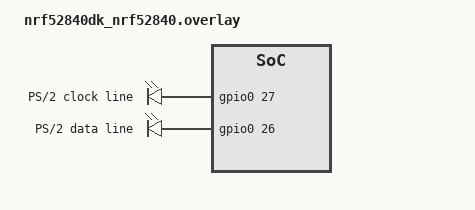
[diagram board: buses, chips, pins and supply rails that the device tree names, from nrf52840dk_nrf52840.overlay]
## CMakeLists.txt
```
# SPDX-License-Identifier: Apache-2.0

cmake_minimum_required(VERSION 3.13.1)
find_package(Zephyr REQUIRED HINTS $ENV{ZEPHYR_BASE})
project(peripheral_hids)

target_include_directories(app PRIVATE src/inc)

FILE(GLOB app_sources src/*.c)
target_sources(app PRIVATE
  ${app_sources}
  )
```

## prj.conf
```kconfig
# Incresed stack due to settings API usage
CONFIG_SYSTEM_WORKQUEUE_STACK_SIZE=2048

CONFIG_BT=y
CONFIG_BT_DEBUG_LOG=y
CONFIG_BT_SMP=y
CONFIG_BT_PERIPHERAL=y
CONFIG_BT_DIS=y
CONFIG_BT_BAS=y
CONFIG_BT_DEVICE_NAME="PS2 to bluetooth keyboard adapter"
CONFIG_BT_DEVICE_APPEARANCE=962

CONFIG_BT_SETTINGS=y
CONFIG_FLASH=y
CONFIG_FLASH_PAGE_LAYOUT=y
CONFIG_FLASH_MAP=y
CONFIG_NVS=y
CONFIG_SETTINGS=y
```

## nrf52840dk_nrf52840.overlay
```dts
/ {
    ps2 {
        compatible = "gpio-leds";
        status = "okay";        
        ps2_clk: ps2clk {
            gpios = < &gpio0 27 GPIO_ACTIVE_HIGH >;
            label = "PS/2 clock line";
        };
        ps2_data: ps2data{
            gpios = < &gpio0 26 GPIO_ACTIVE_HIGH >;
            label = "PS/2 data line";
        };
    };
    aliases {
        ps2clk = &ps2_clk;
        ps2data = &ps2_data;
    };    
};

&i2c0{
    status = "disabled";        
};
&i2c1{
    status = "disabled";        
};
```

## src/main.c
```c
/* main.c - Application main entry point */

/*
 * Copyright (c) 2016 Intel Corporation
 *
 * SPDX-License-Identifier: Apache-2.0
 */

#include <zephyr/types.h>
#include <stddef.h>
#include <string.h>
#include <errno.h>
#include <sys/printk.h>
#include <sys/byteorder.h>
#include <zephyr.h>

#include <settings/settings.h>

#include <bluetooth/bluetooth.h>
#include <bluetooth/hci.h>
#include <bluetooth/conn.h>
#include <bluetooth/uuid.h>
#include <bluetooth/gatt.h>

#include "hog.h"
#include "ps2_keyboard.h"
#include "bt_hid_tools.h"

static const struct bt_data ad[] = {
	BT_DATA_BYTES(BT_DATA_FLAGS, (BT_LE_AD_GENERAL | BT_LE_AD_NO_BREDR)),
	BT_DATA_BYTES(BT_DATA_UUID16_ALL,
		      BT_UUID_16_ENCODE(BT_UUID_HIDS_VAL),
		      BT_UUID_16_ENCODE(BT_UUID_BAS_VAL)),
};

static void connected(struct bt_conn *conn, uint8_t err)
{
	char addr[BT_ADDR_LE_STR_LEN];

	bt_addr_le_to_str(bt_conn_get_dst(conn), addr, sizeof(addr));

	if (err) {
		printk("Failed to connect to %s (%u)\n", addr, err);
		return;
	}

	printk("Connected %s\n", addr);

	if (bt_conn_set_security(conn, BT_SECURITY_L2)) {
		printk("Failed to set security\n");
	}
}

static void disconnected(struct bt_conn *conn, uint8_t reason)
{
	char addr[BT_ADDR_LE_STR_LEN];

	bt_addr_le_to_str(bt_conn_get_dst(conn), addr, sizeof(addr));

	printk("Disconnected from %s (reason 0x%02x)\n", addr, reason);
}

static void security_changed(struct bt_conn *conn, bt_security_t level,
			     enum bt_security_err err)
{
	char addr[BT_ADDR_LE_STR_LEN];

	bt_addr_le_to_str(bt_conn_get_dst(conn), addr, sizeof(addr));

	if (!err) {
		printk("Security changed: %s level %u\n", addr, level);
	} else {
		printk("Security failed: %s level %u err %d\n", addr, level,
		       err);
	}
}

static struct bt_conn_cb conn_callbacks = {
	.connected = connected,
	.disconnected = disconnected,
	.security_changed = security_changed,
};

static void bt_ready(int err)
{
	if (err) {
		printk("Bluetooth init failed (err %d)\n", err);
		return;
	}

	printk("Bluetooth initialized\n");

	hog_init();

	if (IS_ENABLED(CONFIG_SETTINGS)) {
		settings_load();
	}

	err = bt_le_adv_start(BT_LE_ADV_CONN_NAME, ad, ARRAY_SIZE(ad), NULL, 0);
	if (err) {
		printk("Advertising failed to start (err %d)\n", err);
		return;
	}

	printk("Advertising successfully started\n");
}

static void auth_passkey_display(struct bt_conn *conn, unsigned int passkey)
{
	char addr[BT_ADDR_LE_STR_LEN];

	bt_addr_le_to_str(bt_conn_get_dst(conn), addr, sizeof(addr));

	printk("Passkey for %s: %06u\n", addr, passkey);
}

static void auth_cancel(struct bt_conn *conn)
{
	char addr[BT_ADDR_LE_STR_LEN];

	bt_addr_le_to_str(bt_conn_get_dst(conn), addr, sizeof(addr));

	printk("Pairing cancelled: %s\n", addr);
}

static struct bt_conn_auth_cb auth_cb_display = {
	.passkey_display = auth_passkey_display,
	.passkey_entry = NULL,
	.cancel = auth_cancel,
};

void main(void)
{
	int err;

	ps2_keyboard_init();

	err = bt_enable(bt_ready);
	if (err) {
		printk("Bluetooth init failed (err %d)\n", err);
		return;
	}

	bt_conn_cb_register(&conn_callbacks);
	bt_conn_auth_cb_register(&auth_cb_display);
	
	int i=0;
	while(1){
		i++;
	    // ps2_keyboard_set_leds(i&1, i&2, i&3 );
		if ( i % 10 == 0) keyboard_print("I'm writing on your keyboard!");
		printk("ps2_keyboard_set_leds\n");
		k_msleep(1000);
		// i%=4;
	}
}
```

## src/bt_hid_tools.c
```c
#include "bt_hid_tools.h"

#include <stdint.h>
#include <zephyr.h>

#include "hog.h"
#include "usb_hid_keys.h"


void keyboard_print(const char* str){
	struct hids_report_keyboard key_report = { .modifier = 0};

	while(*str){
		key_report.keycode[5] = 0;
		hog_set_keyboard_input(&key_report);
		k_msleep(100);
		key_report.keycode[5] = ascii_to_hid(*str++);
		hog_set_keyboard_input(&key_report);
		k_msleep(100);
	}
	
	key_report.keycode[5] = 0;
	hog_set_keyboard_input(&key_report);	
}

int ascii_to_hid(uint8_t ascii)
{
	if (ascii < 32) {
		/* Character not supported */
		return -1;
	} else if (ascii < 48) {
		/* Special characters */
		switch (ascii) {
		case 32:
			return KEY_SPACE;
		case 33:
			return KEY_1;
		case 34:
			return KEY_APOSTROPHE;
		case 35:
			return KEY_3;
		case 36:
			return KEY_4;
		case 37:
			return KEY_5;
		case 38:
			return KEY_7;
		case 39:
			return KEY_APOSTROPHE;
		case 40:
			return KEY_9;
		case 41:
			return KEY_0;
		case 42:
			return KEY_8;
		case 43:
			return KEY_EQUAL;
		case 44:
			return KEY_COMMA;
		case 45:
			return KEY_MINUS;
		case 46:
			return KEY_DOT;
		case 47:
			return KEY_SLASH;
		default:
			return -1;
		}
	} else if (ascii < 58) {
		/* Numbers */
		if (ascii == 48U) {
			return KEY_0;
		} else {
			return ascii - 19;
		}
	} else if (ascii < 65) {
		/* Special characters #2 */
		switch (ascii) {
		case 58:
			return KEY_SEMICOLON;
		case 59:
			return KEY_SEMICOLON;
		case 60:
			return KEY_COMMA;
		case 61:
			return KEY_EQUAL;
		case 62:
			return KEY_DOT;
		case 63:
			return KEY_SLASH;
		case 64:
			return KEY_2;
		default:
			return -1;
		}
	} else if (ascii < 91) {
		/* Uppercase characters */
		return ascii - 61U;
	} else if (ascii < 97) {
		/* Special characters #3 */
		switch (ascii) {
		case 91:
			return KEY_LEFTBRACE;
		case 92:
			return KEY_BACKSLASH;
		case 93:
			return KEY_RIGHTBRACE;
		case 94:
			return KEY_6;
		case 95:
			return KEY_MINUS;
		case 96:
			return KEY_GRAVE;
		default:
			return -1;
		}
	} else if (ascii < 123) {
		/* Lowercase letters */
		return ascii - 93;
	} else if (ascii < 128) {
		/* Special characters #4 */
		switch (ascii) {
		case 123:
			return KEY_LEFTBRACE;
		case 124:
			return KEY_BACKSLASH;
		case 125:
			return KEY_RIGHTBRACE;
		case 126:
			return KEY_GRAVE;
		case 127:
			return KEY_DELETE;
		default:
			return -1;
		}
	}

	return -1;
}
```

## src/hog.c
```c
/** @file
 *  @brief HoG Service sample
 */

/*
 * Copyright (c) 2016 Intel Corporation
 *
 * SPDX-License-Identifier: Apache-2.0
 */

#include <zephyr/types.h>
#include <stddef.h>
#include <string.h>
#include <errno.h>
#include <sys/printk.h>
#include <sys/byteorder.h>
#include <zephyr.h>

#include <bluetooth/bluetooth.h>
#include <bluetooth/hci.h>
#include <bluetooth/conn.h>
#include <bluetooth/uuid.h>
#include <bluetooth/gatt.h>

#include "usb_hid_keys.h"

enum {
	HIDS_REMOTE_WAKE = BIT(0),
	HIDS_NORMALLY_CONNECTABLE = BIT(1),
};

struct hids_info {
	uint16_t version; /* version number of base USB HID Specification */
	uint8_t code; /* country HID Device hardware is localized for. */
	uint8_t flags;
} __packed;

struct hids_report_mouse {
	uint8_t id; /* report id */
	uint8_t type; /* report type */
} __packed;

struct hids_report_keyboard{
	uint8_t modifier;
	uint8_t reserved;
	uint8_t keycode[6];
} __packed;

static struct hids_info info = {
	.version = 0x0000,
	.code = 0x00,
	.flags = HIDS_NORMALLY_CONNECTABLE,
};

enum {
	HIDS_INPUT = 0x01,
	HIDS_OUTPUT = 0x02,
	HIDS_FEATURE = 0x03,
};

static struct hids_report_mouse input_mouse = {
	.id = 0x01,
	.type = HIDS_INPUT,
};

static struct hids_report_keyboard input_keyboard = {
	.modifier = 0x00,
};

static uint8_t simulate_input;
static uint8_t ctrl_point;
static uint8_t report_map_mouse[] = {
	0x05, 0x01, /* Usage Page (Generic Desktop Ctrls) */
	0x09, 0x02, /* Usage (Mouse) */
	0xA1, 0x01, /* Collection (Application) */
	0x09, 0x01, /*   Usage (Pointer) */
	0xA1, 0x00, /*   Collection (Physical) */
	0x05, 0x09, /*     Usage Page (Button) */
	0x19, 0x01, /*     Usage Minimum (0x01) */
	0x29, 0x03, /*     Usage Maximum (0x03) */
	0x15, 0x00, /*     Logical Minimum (0) */
	0x25, 0x01, /*     Logical Maximum (1) */
	0x95, 0x03, /*     Report Count (3) */
	0x75, 0x01, /*     Report Size (1) */
	0x81, 0x02, /*     Input (Data,Var,Abs,No Wrap,Linear,...) */
	0x95, 0x01, /*     Report Count (1) */
	0x75, 0x05, /*     Report Size (5) */
	0x81, 0x03, /*     Input (Const,Var,Abs,No Wrap,Linear,...) */
	0x05, 0x01, /*     Usage Page (Generic Desktop Ctrls) */
	0x09, 0x30, /*     Usage (X) */
	0x09, 0x31, /*     Usage (Y) */
	0x15, 0x81, /*     Logical Minimum (129) */
	0x25, 0x7F, /*     Logical Maximum (127) */
	0x75, 0x08, /*     Report Size (8) */
	0x95, 0x02, /*     Report Count (2) */
	0x81, 0x06, /*     Input (Data,Var,Rel,No Wrap,Linear,...) */
	0xC0,       /*   End Collection */
	0xC0,       /* End Collection */
};

//From http://codeandlife.com/2012/06/18/usb-hid-keyboard-with-v-usb/
static const uint8_t report_map[63] = {   /* USB report descriptor */
    0x05, 0x01,                    // USAGE_PAGE (Generic Desktop)
    0x09, 0x06,                    // USAGE (Keyboard)
    0xa1, 0x01,                    // COLLECTION (Application)
    0x75, 0x01,                    //   REPORT_SIZE (1)
    0x95, 0x08,                    //   REPORT_COUNT (8)
    0x05, 0x07,                    //   USAGE_PAGE (Keyboard)(Key Codes)
    0x19, 0xe0,                    //   USAGE_MINIMUM (Keyboard LeftControl)(224)
    0x29, 0xe7,                    //   USAGE_MAXIMUM (Keyboard Right GUI)(231)
    0x15, 0x00,                    //   LOGICAL_MINIMUM (0)
    0x25, 0x01,                    //   LOGICAL_MAXIMUM (1)
    0x81, 0x02,                    //   INPUT (Data,Var,Abs) ; Modifier byte
    0x95, 0x01,                    //   REPORT_COUNT (1)
    0x75, 0x08,                    //   REPORT_SIZE (8)
    0x81, 0x03,                    //   INPUT (Cnst,Var,Abs) ; Reserved byte
    0x95, 0x05,                    //   REPORT_COUNT (5)
    0x75, 0x01,                    //   REPORT_SIZE (1)
    0x05, 0x08,                    //   USAGE_PAGE (LEDs)
    0x19, 0x01,                    //   USAGE_MINIMUM (Num Lock)
    0x29, 0x05,                    //   USAGE_MAXIMUM (Kana)
    0x91, 0x02,                    //   OUTPUT (Data,Var,Abs) ; LED report
    0x95, 0x01,                    //   REPORT_COUNT (1)
    0x75, 0x03,                    //   REPORT_SIZE (3)
    0x91, 0x03,                    //   OUTPUT (Cnst,Var,Abs) ; LED report padding
    0x95, 0x06,                    //   REPORT_COUNT (6)
    0x75, 0x08,                    //   REPORT_SIZE (8)
    0x15, 0x00,                    //   LOGICAL_MINIMUM (0)
    0x25, 167,                     //   LOGICAL_MAXIMUM (167)  (Normally would be 101, but we want volume buttons)
    0x05, 0x07,                    //   USAGE_PAGE (Keyboard)(Key Codes)
    0x19, 0x00,                    //   USAGE_MINIMUM (Reserved (no event indicated))(0)
    0x29, 167,                     //   USAGE_MAXIMUM (Keyboard Application)(101) (Now 167)
    0x81, 0x00,                    //   INPUT (Data,Ary,Abs)
    0xc0                           // END_COLLECTION
};


static ssize_t read_info(struct bt_conn *conn,
			  const struct bt_gatt_attr *attr, void *buf,
			  uint16_t len, uint16_t offset)
{
	return bt_gatt_attr_read(conn, attr, buf, len, offset, attr->user_data,
				 sizeof(struct hids_info));
}

static ssize_t read_report_map(struct bt_conn *conn,
			       const struct bt_gatt_attr *attr, void *buf,
			       uint16_t len, uint16_t offset)
{
	printk("read_report_map\n");
	return bt_gatt_attr_read(conn, attr, buf, len, offset, report_map,
				 sizeof(report_map));
}

static ssize_t read_report(struct bt_conn *conn,
			   const struct bt_gatt_attr *attr, void *buf,
			   uint16_t len, uint16_t offset)
{
	printk("read_report called, attr = %p\n",attr);
	return bt_gatt_attr_read(conn, attr, buf, len, offset, attr->user_data,
				 sizeof(struct hids_report_keyboard));
}

static void input_ccc_changed(const struct bt_gatt_attr *attr, uint16_t value)
{
	printk("input_ccc_changed\n");
	simulate_input = (value == BT_GATT_CCC_NOTIFY) ? 1 : 0;
}

static ssize_t read_input_report(struct bt_conn *conn,
				 const struct bt_gatt_attr *attr, void *buf,
				 uint16_t len, uint16_t offset)
{
	printk("read_input_report\n");
	return bt_gatt_attr_read(conn, attr, buf, len, offset, NULL, 0);
}

static ssize_t write_ctrl_point(struct bt_conn *conn,
				const struct bt_gatt_attr *attr,
				const void *buf, uint16_t len, uint16_t offset,
				uint8_t flags)
{
	uint8_t *value = attr->user_data;

	if (offset + len > sizeof(ctrl_point)) {
		return BT_GATT_ERR(BT_ATT_ERR_INVALID_OFFSET);
	}

	memcpy(value + offset, buf, len);

	return len;
}

/* HID Service Declaration */
BT_GATT_SERVICE_DEFINE(hog_svc,
	BT_GATT_PRIMARY_SERVICE(BT_UUID_HIDS),
	BT_GATT_CHARACTERISTIC(BT_UUID_HIDS_INFO, BT_GATT_CHRC_READ,
			       BT_GATT_PERM_READ, read_info, NULL, &info),
	BT_GATT_CHARACTERISTIC(BT_UUID_HIDS_REPORT_MAP, BT_GATT_CHRC_READ,
			       BT_GATT_PERM_READ, read_report_map, NULL, NULL),
	BT_GATT_CHARACTERISTIC(BT_UUID_HIDS_REPORT,
			       BT_GATT_CHRC_READ | BT_GATT_CHRC_NOTIFY,
			       BT_GATT_PERM_READ_AUTHEN,
			       read_input_report, NULL, NULL),
	BT_GATT_CCC(input_ccc_changed,
		    BT_GATT_PERM_READ_AUTHEN | BT_GATT_PERM_WRITE_AUTHEN),
	BT_GATT_DESCRIPTOR(BT_UUID_HIDS_REPORT_REF, 
			   BT_GATT_PERM_READ | BT_GATT_CHRC_NOTIFY,
			   read_report, NULL, &input_keyboard),
	BT_GATT_CHARACTERISTIC(BT_UUID_HIDS_CTRL_POINT,
			       BT_GATT_CHRC_WRITE_WITHOUT_RESP,
			       BT_GATT_PERM_WRITE,
			       NULL, write_ctrl_point, &ctrl_point),
);

void trigger_report_notification()
{
	int err = 0;
	if( !simulate_input ){
		printk("host is not ready\n");
		return;
	}
	// printk("trigger_report_notification, simulate_input = %x, ctrl_point = %x\n",simulate_input, ctrl_point );
	err =  bt_gatt_notify(NULL, &hog_svc.attrs[6], &input_keyboard, sizeof(struct hids_report_keyboard));
}

void hog_set_keyboard_input(struct hids_report_keyboard *kb_report)
{
	memcpy(&input_keyboard,kb_report, sizeof(struct hids_report_keyboard));
	printk("%x, %x, %x, %x, %x, %x, %x\n", kb_report->modifier, kb_report->keycode[0],  
															    kb_report->keycode[1],
															    kb_report->keycode[2],
															    kb_report->keycode[3],
															    kb_report->keycode[4],
															    kb_report->keycode[5]);		
	trigger_report_notification();	
}

void hog_init(void)
{
}
```

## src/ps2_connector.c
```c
#include <zephyr.h>
#include <device.h>
#include <drivers/gpio.h>
#include <sys/util.h>
#include <sys/printk.h>
#include <inttypes.h>
#include <kernel.h>
#include "ps2_connector.h"

#define PS2_CLK_NODE DT_ALIAS(ps2clk)
#define PS2_DATA_NODE DT_ALIAS(ps2data)

#if DT_NODE_HAS_STATUS(PS2_CLK_NODE, okay)
#define PS2_CLK_GPIO_LABEL	DT_GPIO_LABEL(PS2_CLK_NODE, gpios)
#define PS2_CLK_GPIO_PIN	DT_GPIO_PIN(PS2_CLK_NODE, gpios)
#endif

#define PS2_GPIO_FLAGS_HIGH (GPIO_INPUT)
#define PS2_GPIO_FLAGS_LOW (GPIO_OUTPUT | GPIO_ACTIVE_HIGH | GPIO_OPEN_DRAIN)

#if DT_NODE_HAS_STATUS(PS2_DATA_NODE, okay)
#define PS2_DATA_GPIO_LABEL	DT_GPIO_LABEL(PS2_DATA_NODE, gpios)
#define PS2_DATA_GPIO_PIN	DT_GPIO_PIN(PS2_DATA_NODE, gpios)
#endif

static struct gpio_callback clk_fall_cb_data;

#define PS2_MSG_QUE_SIZE 20
char __aligned(1) rx_msg_que_buffer[PS2_MSG_QUE_SIZE];
static struct k_msgq rx_msg_que;

static const unsigned char bit_reverse_table[] = {
  0x00, 0x80, 0x40, 0xC0, 0x20, 0xA0, 0x60, 0xE0, 0x10, 0x90, 0x50, 0xD0, 0x30, 0xB0, 0x70, 0xF0, 
  0x08, 0x88, 0x48, 0xC8, 0x28, 0xA8, 0x68, 0xE8, 0x18, 0x98, 0x58, 0xD8, 0x38, 0xB8, 0x78, 0xF8, 
  0x04, 0x84, 0x44, 0xC4, 0x24, 0xA4, 0x64, 0xE4, 0x14, 0x94, 0x54, 0xD4, 0x34, 0xB4, 0x74, 0xF4, 
  0x0C, 0x8C, 0x4C, 0xCC, 0x2C, 0xAC, 0x6C, 0xEC, 0x1C, 0x9C, 0x5C, 0xDC, 0x3C, 0xBC, 0x7C, 0xFC, 
  0x02, 0x82, 0x42, 0xC2, 0x22, 0xA2, 0x62, 0xE2, 0x12, 0x92, 0x52, 0xD2, 0x32, 0xB2, 0x72, 0xF2, 
  0x0A, 0x8A, 0x4A, 0xCA, 0x2A, 0xAA, 0x6A, 0xEA, 0x1A, 0x9A, 0x5A, 0xDA, 0x3A, 0xBA, 0x7A, 0xFA,
  0x06, 0x86, 0x46, 0xC6, 0x26, 0xA6, 0x66, 0xE6, 0x16, 0x96, 0x56, 0xD6, 0x36, 0xB6, 0x76, 0xF6, 
  0x0E, 0x8E, 0x4E, 0xCE, 0x2E, 0xAE, 0x6E, 0xEE, 0x1E, 0x9E, 0x5E, 0xDE, 0x3E, 0xBE, 0x7E, 0xFE,
  0x01, 0x81, 0x41, 0xC1, 0x21, 0xA1, 0x61, 0xE1, 0x11, 0x91, 0x51, 0xD1, 0x31, 0xB1, 0x71, 0xF1,
  0x09, 0x89, 0x49, 0xC9, 0x29, 0xA9, 0x69, 0xE9, 0x19, 0x99, 0x59, 0xD9, 0x39, 0xB9, 0x79, 0xF9, 
  0x05, 0x85, 0x45, 0xC5, 0x25, 0xA5, 0x65, 0xE5, 0x15, 0x95, 0x55, 0xD5, 0x35, 0xB5, 0x75, 0xF5,
  0x0D, 0x8D, 0x4D, 0xCD, 0x2D, 0xAD, 0x6D, 0xED, 0x1D, 0x9D, 0x5D, 0xDD, 0x3D, 0xBD, 0x7D, 0xFD,
  0x03, 0x83, 0x43, 0xC3, 0x23, 0xA3, 0x63, 0xE3, 0x13, 0x93, 0x53, 0xD3, 0x33, 0xB3, 0x73, 0xF3, 
  0x0B, 0x8B, 0x4B, 0xCB, 0x2B, 0xAB, 0x6B, 0xEB, 0x1B, 0x9B, 0x5B, 0xDB, 0x3B, 0xBB, 0x7B, 0xFB,
  0x07, 0x87, 0x47, 0xC7, 0x27, 0xA7, 0x67, 0xE7, 0x17, 0x97, 0x57, 0xD7, 0x37, 0xB7, 0x77, 0xF7, 
  0x0F, 0x8F, 0x4F, 0xCF, 0x2F, 0xAF, 0x6F, 0xEF, 0x1F, 0x9F, 0x5F, 0xDF, 0x3F, 0xBF, 0x7F, 0xFF
};

uint8_t reverse(uint8_t x){
	return bit_reverse_table[x];
}

typedef enum{
	PS2_STATE_IDLE = 0,
	// PS2_STATE_INIT,
	PS2_STATE_DEV_TO_HOST,
	PS2_STATE_HOST_TO_DEV
} PS2_state_e;


static int current_bit_no = 0;
static uint8_t incoming_data; 
static uint8_t outgoing_data;

static volatile PS2_state_e PS2_state = PS2_STATE_IDLE;

static bool odd_parity_check(uint8_t byte){
	byte ^= byte >> 4;
	byte ^= byte >> 2;
	byte ^= byte >> 1;
	return (-byte & 1);	
}

static inline void set_clk_low(){
	const struct device *clk_line = device_get_binding(PS2_CLK_GPIO_LABEL);
	gpio_pin_configure(clk_line, PS2_CLK_GPIO_PIN, PS2_GPIO_FLAGS_LOW);
	gpio_pin_set(clk_line, PS2_CLK_GPIO_PIN, GPIO_OUTPUT_ACTIVE);
}

static inline void set_clk_high_z(){
	const struct device *clk_line = device_get_binding(PS2_CLK_GPIO_LABEL);
	gpio_pin_configure(clk_line, PS2_CLK_GPIO_PIN, PS2_GPIO_FLAGS_HIGH);
}

static inline void set_data_low(){
	const struct device *data_line = device_get_binding(PS2_DATA_GPIO_LABEL);
	gpio_pin_configure(data_line, PS2_DATA_GPIO_PIN, PS2_GPIO_FLAGS_LOW);
	gpio_pin_set(data_line, PS2_DATA_GPIO_PIN, GPIO_OUTPUT_INACTIVE);
}

static inline void set_data_high_z(){
	const struct device *data_line = device_get_binding(PS2_DATA_GPIO_LABEL);
	gpio_pin_configure(data_line, PS2_DATA_GPIO_PIN, PS2_GPIO_FLAGS_HIGH);
}

static void host_to_dev_init_request_to_send(){
	const struct device *clk_line = device_get_binding(PS2_CLK_GPIO_LABEL);
	// const struct device *data_line = device_get_binding(PS2_DATA_GPIO_LABEL);
	// int err;

	printk("host_to_dev_init_request_to_send\n");

	// pull clock low for at least 100us
	set_clk_low();
	k_usleep(110);
	// pull data low 
	set_data_low();
	k_usleep(10);
	// release clock while keeping data low
	set_clk_high_z();
	
	// prepare data for transmission
	current_bit_no = 0;

	// wait for device to pull clock low 
	printk("wait for device to pull clock low \n");
 	gpio_pin_interrupt_configure(clk_line,
					   PS2_CLK_GPIO_PIN,
					   GPIO_INT_EDGE_TO_INACTIVE);
}

/* blocking function */
void ps2_connector_send_byte(uint8_t msg){
	const struct device *data_line = device_get_binding(PS2_DATA_GPIO_LABEL);
	const struct device *clk_line = device_get_binding(PS2_CLK_GPIO_LABEL);

	outgoing_data = msg;

	PS2_state = PS2_STATE_HOST_TO_DEV;
	host_to_dev_init_request_to_send();
	while( PS2_state != PS2_STATE_IDLE){
		// allow other threads do their job while sending
		k_msleep(1);
	};
	// Wait for the device to release Data and Clock
	while( gpio_pin_get(data_line, PS2_DATA_GPIO_PIN) == 0 ||
		   gpio_pin_get(clk_line, PS2_CLK_GPIO_PIN) == 0 ) {
	}

}

static void host_to_dev_serve_falling_clk(){
	int current_bit = 0;
	printk("host_to_dev_serve_falling_clk\n");
	PS2_state = PS2_STATE_DEV_TO_HOST;
	// start bit was already send by host_to_dev_init_request_to_send
	current_bit = 0x01 & (outgoing_data >> current_bit_no);
	if(current_bit){
		set_data_high_z();
	}
	else
	{
		set_data_low();
	}
	// parity bit
	if(current_bit_no == 8){
		current_bit = !odd_parity_check(outgoing_data);
		if(current_bit){
			set_data_high_z();
		}
		else
		{
			set_data_low();
		}		
	}
	// stop bit 
	if(current_bit_no == 8){
		set_data_high_z();
	}
	if(current_bit_no == 9){
		set_data_high_z();
		// consider transmission done
		PS2_state = PS2_STATE_IDLE;
	}
	current_bit_no++;
	current_bit_no %= 10;

}

static void dev_to_host_serve_falling_clk(){
	const struct device *data_line = device_get_binding(PS2_DATA_GPIO_LABEL);
	int current_bit = 0;

	// printk("a\n");

	// k_usleep(15);
	current_bit = gpio_pin_get(data_line, PS2_DATA_GPIO_PIN);

	// start bit
	if(current_bit_no == 0){
		if(current_bit != 0){
			//generate error
			printk("ERROR: dev_to_host_serve_falling_clk: incoming data start bit check failed!\n");
			current_bit_no = 0;
			return;
		}
	}
	// 8 data bits
	if(current_bit_no < 9){
		// LSB first
		incoming_data <<= 1;
		incoming_data &= 0b11111110;
		incoming_data |= current_bit;
	}
	// parity bit
	if(current_bit_no == 9){
		if(odd_parity_check(incoming_data) == current_bit){
			// generate error
			printk("ERROR: dev_to_host_serve_falling_clk: incoming data parity check failed, data: 0x%x!\n", incoming_data);
			current_bit_no = 0;
			return;			
		}
	}
	// stop bit
	if(current_bit_no == 10){
		if(current_bit != 1){
			//generate error
			printk("ERROR: dev_to_host_serve_falling_clk: incoming data expected high stop bit, got low instead!\n");
			current_bit_no = 0;
			return;			
		}
		else{
			// code ok, push to msg queue
			// printk( "PS2_connector: recived code: 0x%x\n", incoming_data);
			k_msgq_put(&rx_msg_que, (void*) &incoming_data,K_NO_WAIT);
		}
	}
	current_bit_no++;
	// no more than 10
	current_bit_no %= 11;
}

static void clk_fall_cb(const struct device *dev, struct gpio_callback *cb,
		    uint32_t pins)
{
	switch (PS2_state)
	{
	case PS2_STATE_DEV_TO_HOST:
	case PS2_STATE_IDLE:
		dev_to_host_serve_falling_clk();
		break;
	case PS2_STATE_HOST_TO_DEV:
		host_to_dev_serve_falling_clk();
		break;
	default:
		break;
	}
}

uint8_t ps2_connector_get_next_code(){
	uint8_t result;
	k_msgq_get(&rx_msg_que, &result, K_FOREVER);
	result = reverse(result);
	// printk("processing code: %x\n", result);
	return result;
}

void ps2_connector_init(){
	const struct device *data_line = device_get_binding(PS2_DATA_GPIO_LABEL);
	const struct device *clk_line = device_get_binding(PS2_CLK_GPIO_LABEL);
	int err = 0;

	k_msgq_init(&rx_msg_que, rx_msg_que_buffer, 1, PS2_MSG_QUE_SIZE);
	// power on keyboard
	
	// wait until data and clock are high 
	printk("wait until data and clock are high\n");
	err = gpio_pin_configure(clk_line, PS2_CLK_GPIO_PIN, GPIO_INPUT);
	if (err != 0) {
		printk("Error %d: failed to configure %s pin %d\n",
		       err, PS2_CLK_GPIO_LABEL, PS2_CLK_GPIO_PIN);
		return;
	}
	err = gpio_pin_configure(data_line, PS2_DATA_GPIO_PIN, GPIO_INPUT);
	if (err != 0) {
		printk("Error %d: failed to configure %s pin %d\n",
		       err, PS2_DATA_GPIO_LABEL, PS2_DATA_GPIO_PIN);
		return;
	}
	while( gpio_pin_get(data_line, PS2_DATA_GPIO_PIN) == 0 ||
		   gpio_pin_get(clk_line, PS2_CLK_GPIO_PIN) == 0 ) {
	}
	// start receiving data
	PS2_state = PS2_STATE_DEV_TO_HOST;
	gpio_pin_interrupt_configure(clk_line,
					   PS2_CLK_GPIO_PIN,
					   GPIO_INT_EDGE_TO_INACTIVE);	
	gpio_init_callback(&clk_fall_cb_data, clk_fall_cb, BIT(PS2_CLK_GPIO_PIN));
	gpio_add_callback(clk_line, &clk_fall_cb_data);

	// wait for 0xAA - BAT code
	// printk("wait for 0xAA - BAT code!\n");

	printk("PS2 keyboard ready!\n");


}
```

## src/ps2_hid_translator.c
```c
#include "keys_by_ps2_scancode.h"
#include <stdbool.h>
#include <stdint.h>
#include <zephyr.h>
#include "hog.h"
#include "ps2_connector.h"

#define EXTENDED_CODE 0xe0
#define BREAK_CODE 0xf0

static const uint8_t pause_break_code[] = {0xE1, 0x14, 0x77, 0xE1, 0xF0, 0x14, 0xf0, 0x77};

static const uint8_t sys_req_make[] = { 0xE0, 0x12, 0xE0, 0x7C};
static const uint8_t sys_req_break[] = { 0xE0, 0xF0, 0x7C, 0xE0, 0xF0, 0x12};

static struct hids_report_keyboard key_report = { .modifier = 0};

static int pos_at_pressed_keys(uint8_t key){
    for( int i = 0; i <6; ++i){
        if(key_report.keycode[i] == key){
            return i;
        }          
    }
    return -1;    
}

static void press_mod_key(uint8_t key){
    // printk("press mod key: %x\n", key);
    key_report.modifier |= key;
    hog_set_keyboard_input(&key_report);
}

static void release_mod_key(uint8_t key){
    // printk("relase mod: %x\n", key);
    key_report.modifier &= ~key;
    hog_set_keyboard_input(&key_report);
}

static void press_key(uint8_t key){
    // printk("press key: %x\n", key);
    if(key == KEY_UNKNOWN) return;
    if(pos_at_pressed_keys(key) == -1){
        for(int i = 5; i >=0; --i){
            if(key_report.keycode[i] == 0){
               key_report.keycode[i] = key;
               hog_set_keyboard_input(&key_report);
               return; 
            }
        }
        /* there's more than 6 keys pressed at once, 
           drop the oldest*/
        key_report.keycode[5] = key;
        hog_set_keyboard_input(&key_report);
    }
}

static void release_key(uint8_t key){
    int pos; 
    // printk("relase key: %x\n", key);
    if(key == KEY_UNKNOWN) return;

    pos = pos_at_pressed_keys(key);
    
    if( pos == -1) return;
    key_report.keycode[pos] = 0;
    hog_set_keyboard_input(&key_report);
}

static void press_pause_break(){
    // printk("press pause / break\n");
    press_key(KEY_PAUSE);
    k_msleep(10);
    release_key(KEY_PAUSE);
}

static uint8_t ps2_extended_code_to_hid_key(uint8_t code){
    switch (code)
    {
        case 0x1F: return KEY_LEFTMETA;
        case 0x11: return KEY_RIGHTALT;
        case 0x27: return KEY_RIGHTMETA;
        case 0x2F: return KEY_PROPS;
        case 0x14: return KEY_RIGHTCTRL;
        case 0x70: return KEY_INSERT;
        case 0x6C: return KEY_HOME;
        case 0x7D: return KEY_PAGEUP;
        case 0x71: return KEY_DELETE;
        case 0x69: return KEY_END;
        case 0x7A: return KEY_PAGEDOWN;
        case 0x75: return KEY_UP;
        case 0x6B: return KEY_LEFT;
        case 0x72: return KEY_DOWN;
        case 0x74: return KEY_RIGHT;
        case 0x4A: return KEY_KPSLASH;
        case 0x5A: return KEY_ENTER;
        default: return KEY_UNKNOWN;
    }
}

void ps2_hid_translator_parse_next_scancode(){
    uint8_t code; //read from que
    uint8_t key;
    int i;

    code = ps2_connector_get_next_code();

    switch (code)
    {
        
    case 0x11: /* LALT*/
    case 0x12: /* LSHIFT*/ 
    case 0x14: /* LCTRL*/
    case 0x59: /* RSHIFT*/ 
        key = ps2_scan_code_to_usb_hid_key[code];
        press_mod_key(key);        
        break;
    case EXTENDED_CODE:
        code = ps2_connector_get_next_code();
        if(code == BREAK_CODE) {
            code = ps2_connector_get_next_code();
            if(code == sys_req_break[2]){
                for( i = 3; i< sizeof(sys_req_break); ++i ){
                    code = ps2_connector_get_next_code();
                    if(sys_req_break[i] != code){
                        return;
                    }
                }
                release_key(KEY_SYSRQ);
                return;         
            }  
            key = ps2_extended_code_to_hid_key(code); 
            if(key == KEY_RIGHTALT  ||
               key == KEY_RIGHTCTRL ||
               key == KEY_LEFTMETA  ||
               key == KEY_RIGHTMETA ){
                release_mod_key(key);
            }
            else{
                release_key(key);
            }         
        }
        else if(code == sys_req_make[1]){

            for( i = 2; i< sizeof(sys_req_make); ++i ){
                code = ps2_connector_get_next_code();
                if(sys_req_make[i] != code){
                    return;
                }
            }
            press_key(KEY_SYSRQ);          
        }      
        else{
            key = ps2_extended_code_to_hid_key(code);
            if(key == KEY_RIGHTALT  ||
               key == KEY_RIGHTCTRL ||
               key == KEY_LEFTMETA  ||
               key == KEY_RIGHTMETA ){
                press_mod_key(key);
            }
            else
            {
                press_key(key); 
            }     
        }
        break;
    case BREAK_CODE:
        code = ps2_connector_get_next_code();
        key = ps2_scan_code_to_usb_hid_key[code];
        if( code == 0x11 || /* LALT*/
            code == 0x12 || /* LSHIFT*/ 
            code == 0x14 || /* LCTRL*/
            code == 0x59    /* RSHIFT*/ ){
                release_mod_key(key);
                break;
            }
        release_key(key);
        break; 
    case 0xE1: /* PAUSE_BREAK*/
        // printk("Got 0xe1\n");
        for( i = 1; i< sizeof(pause_break_code); ++i ){
            code = ps2_connector_get_next_code();
            if(pause_break_code[i] != code){
                return;
            }
        }
        press_pause_break();
        break;      
    default:
        key = ps2_scan_code_to_usb_hid_key[code];
        press_key(key);
        break;
    }
}
```

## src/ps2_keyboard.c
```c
#include "ps2_keyboard.h"

#include <zephyr.h>
#include <device.h>
#include <drivers/gpio.h>
#include <sys/util.h>
#include <sys/printk.h>
#include <inttypes.h>
#include <kernel.h>
#include <stdint.h>

#include "hog.h"
#include "usb_hid_keys.h"
#include "bt_hid_tools.h"
#include "ps2_connector.h"
#include "ps2_hid_translator.h"

#define PS2_KEYBOARD_THREAD_PRIORITY 5

#define SCROLL_LOCK_LED_MASK 0x01
#define NUM_LOCK_LED_MASK (0x01<<1)
#define CAPS_LOCK_LED_MASK (0x01<<2)

#define PS2_CMD_SET_LEDS 0xed 

void ps2_keyboard_set_leds(uint8_t scroll_lock, uint8_t num_lock, uint8_t caps_lock ){
	uint8_t command = 0;
	if(scroll_lock) command |= SCROLL_LOCK_LED_MASK;
	if(num_lock) command |= NUM_LOCK_LED_MASK;
	if(caps_lock) command |= CAPS_LOCK_LED_MASK;

	ps2_connector_send_byte(PS2_CMD_SET_LEDS);
	ps2_connector_send_byte(command);
} 

static void ps2_keyboard_thread(void *p1, void *p2, void *p3){
	while(1){
		ps2_hid_translator_parse_next_scancode();
		k_msleep(1);
	}
}

static K_THREAD_STACK_DEFINE(ps2_keyboard_thread_stack, 32 * 1024);
static struct k_thread ps2_keyboard_thread_data;

void ps2_keyboard_start_worker_thread(){
	k_thread_create(&ps2_keyboard_thread_data, ps2_keyboard_thread_stack,
		K_THREAD_STACK_SIZEOF(ps2_keyboard_thread_stack), ps2_keyboard_thread,
		NULL, NULL, NULL, PS2_KEYBOARD_THREAD_PRIORITY, 0, K_NO_WAIT);   
}

void ps2_keyboard_init()
{
	ps2_connector_init();
	ps2_keyboard_start_worker_thread();
}
```
